# ATmega128RFA1 register map
Vendor: Atmel; File version: 1.0
CPU: other r0p0, little endian, no MPU, no FPU, 4 interrupt priority bits
Registers are 8-bit, read-write, reset 0x0 unless marked. A register's access mark holds for its fields unless they carry their own. Offsets are from the block's base; [hi:lo] are bit positions; 'fields as' and 'values as' point back to an identical list.

## JTAG — JTAG Interface
Base 0x00800051
0x00 OCDR — On-Chip Debug Register (write-only for debugger)
  [7:0] OCDR — On-Chip Debug Register Data
    0=REFER_TO_THE_DEBUGGER_DOCUMENTATION_FOR_FURTHER_INFORMATION_ON_HOW_TO_USE_THIS_REGISTER
0x03 MCUSR — MCU Status Register
  [4] JTRF — JTAG Reset Flag
0x04 MCUCR — MCU Control Register
  [7] JTD — JTAG Interface Disable

## LOCKBIT — Lockbits
Base 0x00800000
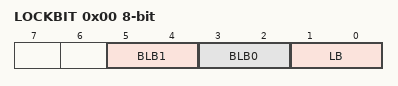
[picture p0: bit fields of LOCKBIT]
0x00 LOCKBIT
  [5:4] BLB1 — Boot Loader Protection Mode
    0=LPM_SPM_DISABLE (LPM and SPM prohibited in Boot Section); 1=LPM_DISABLE (LPM prohibited in Boot Section); 2=SPM_DISABLE (SPM prohibited in Boot Section); 3=NO_LOCK (No lock on SPM and LPM in Boot Section)
  [3:2] BLB0 — Boot Loader Protection Mode
    0=LPM_SPM_DISABLE (LPM and SPM prohibited in Application Section); 1=LPM_DISABLE (LPM prohibited in Application Section); 2=SPM_DISABLE (SPM prohibited in Application Section); 3=NO_LOCK (No lock on SPM and LPM in Application Section)
  [1:0] LB — Memory Lock
    0=PROG_VER_DISABLED (Further programming and verification disabled); 2=PROG_DISABLED (Further programming disabled); 3=NO_LOCK (No memory lock features enabled)

## PORTA — I/O Port
Base 0x00800020
0x00 PINA — Port A Input Pins Address
0x01 DDRA — Port A Data Direction Register
0x02 PORTA — Port A Data Register

## PORTB — I/O Port
Base 0x00800023
0x00 PINB — Port B Input Pins Address
0x01 DDRB — Port B Data Direction Register
0x02 PORTB — Port B Data Register

## PORTC — I/O Port
Base 0x00800026
0x00 PINC — Port C Input Pins Address
0x01 DDRC — Port C Data Direction Register
0x02 PORTC — Port C Data Register

## PORTD — I/O Port
Base 0x00800029
0x00 PIND — Port D Input Pins Address
0x01 DDRD — Port D Data Direction Register
0x02 PORTD — Port D Data Register

## PORTE — I/O Port
Base 0x0080002C
0x00 PINE — Port E Input Pins Address
0x01 DDRE — Port E Data Direction Register
0x02 PORTE — Port E Data Register

## PORTF — I/O Port
Base 0x0080002F
0x00 PINF — Port F Input Pins Address
0x01 DDRF — Port F Data Direction Register
0x02 PORTF — Port F Data Register

## PORTG — I/O Port
Base 0x00800032
0x00 PING — Port G Input Pins Address
0x01 DDRG — Port G Data Direction Register
0x02 PORTG — Port G Data Register

## PWRCTRL — Power Controller
Base 0x00800055
0x00 MCUCR — MCU Control Register
  [4] PUD — Pull-up Disable
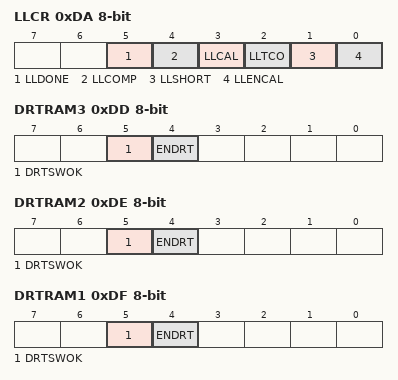
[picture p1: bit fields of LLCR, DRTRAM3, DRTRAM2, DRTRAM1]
0xDA LLCR — Low Leakage Voltage Regulator Control Register
  [5] LLDONE — Calibration Done
  [4] LLCOMP — Comparator Output
  [3] LLCAL — Calibration Active
  [2] LLTCO — Temperature Coefficient of Current Source
  [1] LLSHORT — Short Lower Calibration Circuit
  [0] LLENCAL — Enable Automatic Calibration
0xDB LLDRL — Low Leakage Voltage Regulator Data Register (Low-Byte)
  [3:0] LLDRL — Low-Byte Data Register Bits
    0=CALIBRATION_LIMIT_FOR_FAST_PROCESS_CORNER_HIGH_OUTPUT_VOLTAGE; 8=CALIBRATION_LIMIT_FOR_SLOW_PROCESS_CORNER_LOW_OUTPUT_VOLTAGE
0xDC LLDRH — Low Leakage Voltage Regulator Data Register (High-Byte)
  [4:0] LLDRH — High-Byte Data Register Bits
    0=CALIBRATION_LIMIT_FOR_FAST_PROCESS_CORNER_HIGH_OUTPUT_VOLTAGE; 16=CALIBRATION_LIMIT_FOR_SLOW_PROCESS_CORNER_LOW_OUTPUT_VOLTAGE
0xDD DRTRAM3 — Data Retention Configuration Register of SRAM 3
  [5] DRTSWOK — DRT Switch OK
  [4] ENDRT — Enable SRAM Data Retention
0xDE DRTRAM2 — Data Retention Configuration Register of SRAM 2
  [5] DRTSWOK — DRT Switch OK
  [4] ENDRT — Enable SRAM Data Retention
0xDF DRTRAM1 — Data Retention Configuration Register of SRAM 1
  [5] DRTSWOK — DRT Switch OK
  [4] ENDRT — Enable SRAM Data Retention
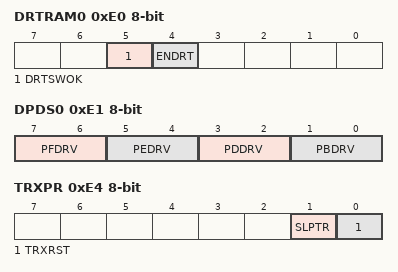
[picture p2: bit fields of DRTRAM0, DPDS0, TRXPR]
0xE0 DRTRAM0 — Data Retention Configuration Register of SRAM 0
  [5] DRTSWOK — DRT Switch OK
  [4] ENDRT — Enable SRAM Data Retention
0xE1 DPDS0 — Port Driver Strength Register 0
  [all] fields
    0=PAD_IO_2MA (2 mA); 1=PAD_IO_4MA (4 mA); 2=PAD_IO_6MA (6 mA); 3=PAD_IO_8MA (8 mA)
  [7:6] PFDRV — Driver Strength Port F
  [5:4] PEDRV — Driver Strength Port E
  [3:2] PDDRV — Driver Strength Port D
  [1:0] PBDRV — Driver Strength Port B
0xE2 DPDS1 — Port Driver Strength Register 1
  [1:0] PGDRV — Driver Strength Port G
    values as the fields of DPDS0
0xE4 TRXPR — Transceiver Pin Register
  [1] SLPTR — Multi-purpose Transceiver Control Bit
  [0] TRXRST — Force Transceiver Reset
